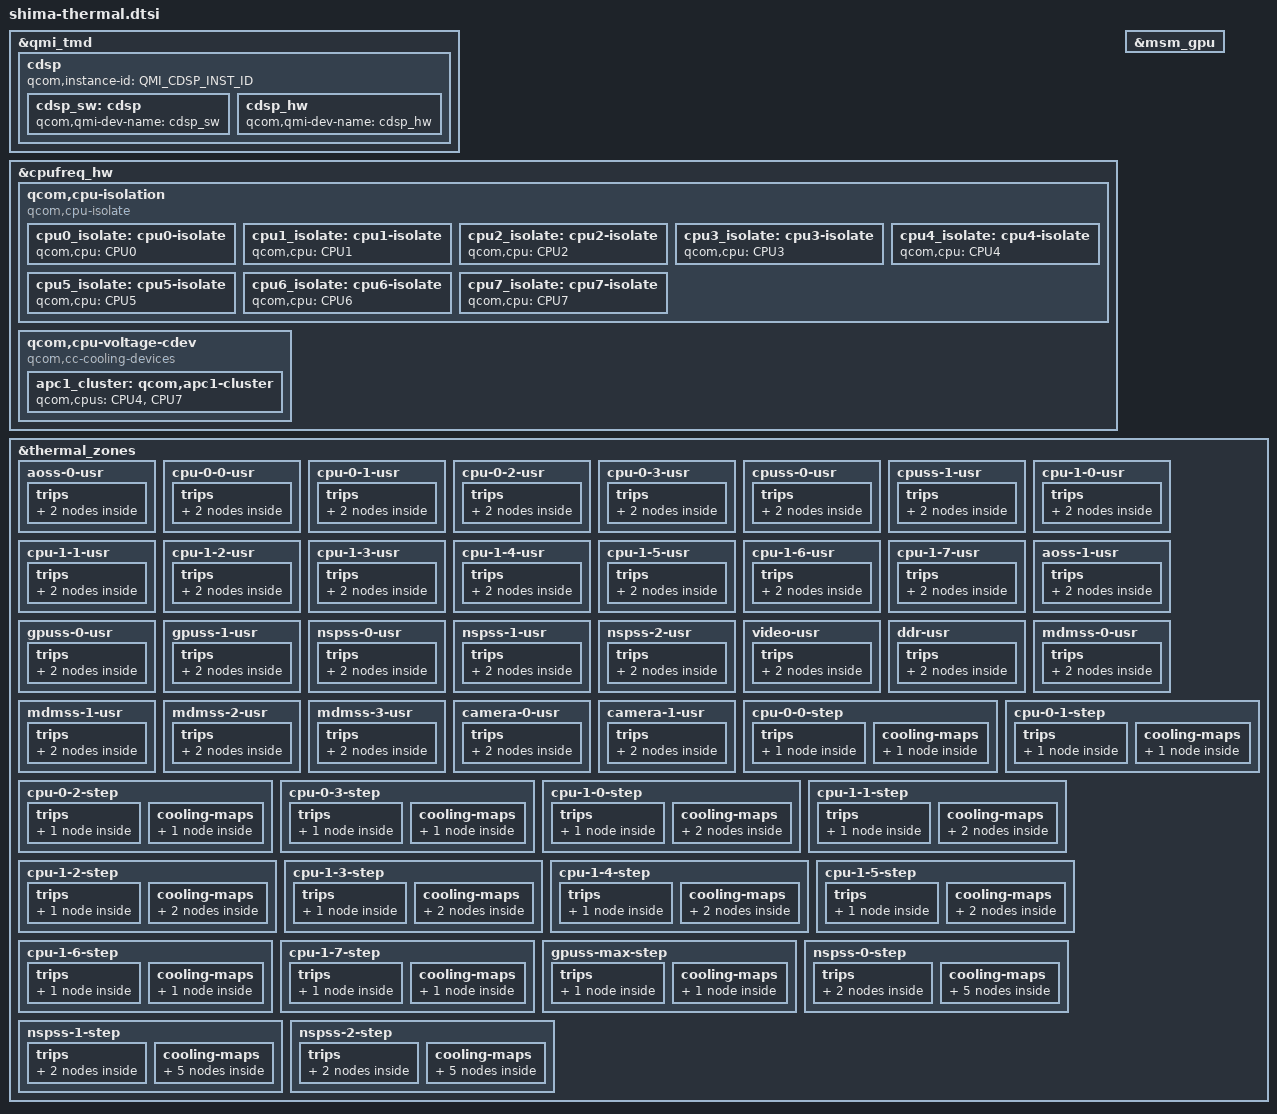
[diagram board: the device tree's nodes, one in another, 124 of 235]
#include <dt-bindings/thermal/thermal_qti.h>
#include "lahaina-thermal-modem.dtsi"

&qmi_tmd {
	cdsp {
		qcom,instance-id = <QMI_CDSP_INST_ID>;

		cdsp_sw: cdsp {
			qcom,qmi-dev-name = "cdsp_sw";
			#cooling-cells = <2>;
		};

		cdsp_hw: cdsp_hw {
			qcom,qmi-dev-name = "cdsp_hw";
			#cooling-cells = <2>;
		};
	};
};

&cpufreq_hw {
	qcom,cpu-isolation {
		compatible = "qcom,cpu-isolate";
		cpu0_isolate: cpu0-isolate {
			qcom,cpu = <&CPU0>;
			#cooling-cells = <2>;
		};

		cpu1_isolate: cpu1-isolate {
			qcom,cpu = <&CPU1>;
			#cooling-cells = <2>;
		};

		cpu2_isolate: cpu2-isolate {
			qcom,cpu = <&CPU2>;
			#cooling-cells = <2>;
		};

		cpu3_isolate: cpu3-isolate {
			qcom,cpu = <&CPU3>;
			#cooling-cells = <2>;
		};

		cpu4_isolate: cpu4-isolate {
			qcom,cpu = <&CPU4>;
			#cooling-cells = <2>;
		};

		cpu5_isolate: cpu5-isolate {
			qcom,cpu = <&CPU5>;
			#cooling-cells = <2>;
		};

		cpu6_isolate: cpu6-isolate {
			qcom,cpu = <&CPU6>;
			#cooling-cells = <2>;
		};

		cpu7_isolate: cpu7-isolate {
			qcom,cpu = <&CPU7>;
			#cooling-cells = <2>;
		};
	};

	qcom,cpu-voltage-cdev {
		compatible = "qcom,cc-cooling-devices";
		apc1_cluster: qcom,apc1-cluster {
			qcom,cpus = <&CPU4 &CPU7>;
			#cooling-cells = <2>;
		};
	};
};

&msm_gpu {
	#cooling-cells = <2>;
};

&thermal_zones {
	aoss-0-usr {
		polling-delay-passive = <0>;
		polling-delay = <0>;
		thermal-governor = "user_space";
		thermal-sensors = <&tsens0 0>;
		trips {
			active-config0 {
				temperature = <125000>;
				hysteresis = <1000>;
				type = "passive";
			};

			reset-mon-cfg {
				temperature = <115000>;
				hysteresis = <5000>;
				type = "passive";
			};
		};
	};

	cpu-0-0-usr {
		polling-delay-passive = <0>;
		polling-delay = <0>;
		thermal-governor = "user_space";
		thermal-sensors = <&tsens0 1>;
		trips {
			active-config0 {
				temperature = <125000>;
				hysteresis = <1000>;
				type = "passive";
			};

			reset-mon-cfg {
				temperature = <115000>;
				hysteresis = <5000>;
				type = "passive";
			};
		};
	};

	cpu-0-1-usr {
		polling-delay-passive = <0>;
		polling-delay = <0>;
		thermal-governor = "user_space";
		thermal-sensors = <&tsens0 2>;
		trips {
			active-config0 {
				temperature = <125000>;
				hysteresis = <1000>;
				type = "passive";
			};

			reset-mon-cfg {
				temperature = <115000>;
				hysteresis = <5000>;
				type = "passive";
			};
		};
	};

	cpu-0-2-usr {
		polling-delay-passive = <0>;
		polling-delay = <0>;
		thermal-governor = "user_space";
		thermal-sensors = <&tsens0 3>;
		trips {
			active-config0 {
				temperature = <125000>;
				hysteresis = <1000>;
				type = "passive";
			};

			reset-mon-cfg {
				temperature = <115000>;
				hysteresis = <5000>;
				type = "passive";
			};
		};
	};

	cpu-0-3-usr {
		polling-delay-passive = <0>;
		polling-delay = <0>;
		thermal-governor = "user_space";
		thermal-sensors = <&tsens0 4>;
		trips {
			active-config0 {
				temperature = <125000>;
				hysteresis = <1000>;
				type = "passive";
			};

			reset-mon-cfg {
				temperature = <115000>;
				hysteresis = <5000>;
				type = "passive";
			};
		};
	};

	cpuss-0-usr {
		polling-delay-passive = <0>;
		polling-delay = <0>;
		thermal-governor = "user_space";
		thermal-sensors = <&tsens0 5>;
		trips {
			active-config0 {
				temperature = <125000>;
				hysteresis = <1000>;
				type = "passive";
			};

			reset-mon-cfg {
				temperature = <115000>;
				hysteresis = <5000>;
				type = "passive";
			};
		};
	};

	cpuss-1-usr {
		polling-delay-passive = <0>;
		polling-delay = <0>;
		thermal-governor = "user_space";
		thermal-sensors = <&tsens0 6>;
		trips {
			active-config0 {
				temperature = <125000>;
				hysteresis = <1000>;
				type = "passive";
			};

			reset-mon-cfg {
				temperature = <115000>;
				hysteresis = <5000>;
				type = "passive";
			};
		};
	};

	cpu-1-0-usr {
		polling-delay-passive = <0>;
		polling-delay = <0>;
		thermal-governor = "user_space";
		thermal-sensors = <&tsens0 7>;
		trips {
			active-config0 {
				temperature = <125000>;
				hysteresis = <1000>;
				type = "passive";
			};

			reset-mon-cfg {
				temperature = <115000>;
				hysteresis = <5000>;
				type = "passive";
			};
		};
	};

	cpu-1-1-usr {
		polling-delay-passive = <0>;
		polling-delay = <0>;
		thermal-governor = "user_space";
		thermal-sensors = <&tsens0 8>;
		trips {
			active-config0 {
				temperature = <125000>;
				hysteresis = <1000>;
				type = "passive";
			};

			reset-mon-cfg {
				temperature = <115000>;
				hysteresis = <5000>;
				type = "passive";
			};
		};
	};

	cpu-1-2-usr {
		polling-delay-passive = <0>;
		polling-delay = <0>;
		thermal-governor = "user_space";
		thermal-sensors = <&tsens0 9>;
		trips {
			active-config0 {
				temperature = <125000>;
				hysteresis = <1000>;
				type = "passive";
			};

			reset-mon-cfg {
				temperature = <115000>;
				hysteresis = <5000>;
				type = "passive";
			};
		};
	};

	cpu-1-3-usr {
		polling-delay-passive = <0>;
		polling-delay = <0>;
		thermal-governor = "user_space";
		thermal-sensors = <&tsens0 10>;
		trips {
			active-config0 {
				temperature = <125000>;
				hysteresis = <1000>;
				type = "passive";
			};

			reset-mon-cfg {
				temperature = <115000>;
				hysteresis = <5000>;
				type = "passive";
			};
		};
	};

	cpu-1-4-usr {
		polling-delay-passive = <0>;
		polling-delay = <0>;
		thermal-governor = "user_space";
		thermal-sensors = <&tsens0 11>;
		trips {
			active-config0 {
				temperature = <125000>;
				hysteresis = <1000>;
				type = "passive";
			};

			reset-mon-cfg {
				temperature = <115000>;
				hysteresis = <5000>;
				type = "passive";
			};
		};
	};

	cpu-1-5-usr {
		polling-delay-passive = <0>;
		polling-delay = <0>;
		thermal-governor = "user_space";
		thermal-sensors = <&tsens0 12>;
		trips {
			active-config0 {
				temperature = <125000>;
				hysteresis = <1000>;
				type = "passive";
			};

			reset-mon-cfg {
				temperature = <115000>;
				hysteresis = <5000>;
				type = "passive";
			};
		};
	};

	cpu-1-6-usr {
		polling-delay-passive = <0>;
		polling-delay = <0>;
		thermal-governor = "user_space";
		thermal-sensors = <&tsens0 13>;
		trips {
			active-config0 {
				temperature = <125000>;
				hysteresis = <1000>;
				type = "passive";
			};

			reset-mon-cfg {
				temperature = <115000>;
				hysteresis = <5000>;
				type = "passive";
			};
		};
	};

	cpu-1-7-usr {
		polling-delay-passive = <0>;
		polling-delay = <0>;
		thermal-governor = "user_space";
		thermal-sensors = <&tsens0 14>;
		trips {
			active-config0 {
				temperature = <125000>;
				hysteresis = <1000>;
				type = "passive";
			};

			reset-mon-cfg {
				temperature = <115000>;
				hysteresis = <5000>;
				type = "passive";
			};
		};
	};

	aoss-1-usr {
		polling-delay-passive = <0>;
		polling-delay = <0>;
		thermal-governor = "user_space";
		thermal-sensors = <&tsens1 0>;
		trips {
			active-config0 {
				temperature = <125000>;
				hysteresis = <1000>;
				type = "passive";
			};

			reset-mon-cfg {
				temperature = <115000>;
				hysteresis = <5000>;
				type = "passive";
			};
		};
	};

	gpuss-0-usr {
		polling-delay-passive = <0>;
		polling-delay = <0>;
		thermal-governor = "user_space";
		thermal-sensors = <&tsens1 1>;
		trips {
			active-config0 {
				temperature = <125000>;
				hysteresis = <1000>;
				type = "passive";
			};

			reset-mon-cfg {
				temperature = <115000>;
				hysteresis = <5000>;
				type = "passive";
			};
		};
	};

	gpuss-1-usr {
		polling-delay-passive = <0>;
		polling-delay = <0>;
		thermal-governor = "user_space";
		thermal-sensors = <&tsens1 2>;
		trips {
			active-config0 {
				temperature = <125000>;
				hysteresis = <1000>;
				type = "passive";
			};

			reset-mon-cfg {
				temperature = <115000>;
				hysteresis = <5000>;
				type = "passive";
			};
		};
	};

	nspss-0-usr {
		polling-delay-passive = <0>;
		polling-delay = <0>;
		thermal-governor = "user_space";
		thermal-sensors = <&tsens1 3>;
		trips {
			active-config0 {
				temperature = <125000>;
				hysteresis = <1000>;
				type = "passive";
			};

			reset-mon-cfg {
				temperature = <115000>;
				hysteresis = <5000>;
				type = "passive";
			};
		};
	};

	nspss-1-usr {
		polling-delay-passive = <0>;
		polling-delay = <0>;
		thermal-governor = "user_space";
		thermal-sensors = <&tsens1 4>;
		trips {
			active-config0 {
				temperature = <125000>;
				hysteresis = <1000>;
				type = "passive";
			};

			reset-mon-cfg {
				temperature = <115000>;
				hysteresis = <5000>;
				type = "passive";
			};
		};
	};

	nspss-2-usr {
		polling-delay-passive = <0>;
		polling-delay = <0>;
		thermal-governor = "user_space";
		thermal-sensors = <&tsens1 5>;
		trips {
			active-config0 {
				temperature = <125000>;
				hysteresis = <1000>;
				type = "passive";
			};

			reset-mon-cfg {
				temperature = <115000>;
				hysteresis = <5000>;
				type = "passive";
			};
		};
	};

	video-usr {
		polling-delay-passive = <0>;
		polling-delay = <0>;
		thermal-governor = "user_space";
		thermal-sensors = <&tsens1 6>;
		trips {
			active-config0 {
				temperature = <125000>;
				hysteresis = <1000>;
				type = "passive";
			};

			reset-mon-cfg {
				temperature = <115000>;
				hysteresis = <5000>;
				type = "passive";
			};
		};
	};

	ddr-usr {
		polling-delay-passive = <0>;
		polling-delay = <0>;
		thermal-governor = "user_space";
		thermal-sensors = <&tsens1 7>;
		trips {
			active-config0 {
				temperature = <125000>;
				hysteresis = <1000>;
				type = "passive";
			};

			reset-mon-cfg {
				temperature = <115000>;
				hysteresis = <5000>;
				type = "passive";
			};
		};
	};

	mdmss-0-usr {
		polling-delay-passive = <0>;
		polling-delay = <0>;
		thermal-governor = "user_space";
		thermal-sensors = <&tsens1 8>;
		trips {
			active-config0 {
				temperature = <125000>;
				hysteresis = <1000>;
				type = "passive";
			};

			reset-mon-cfg {
				temperature = <115000>;
				hysteresis = <5000>;
				type = "passive";
			};
		};
	};

	mdmss-1-usr {
		polling-delay-passive = <0>;
		polling-delay = <0>;
		thermal-governor = "user_space";
		thermal-sensors = <&tsens1 9>;
		trips {
			active-config0 {
				temperature = <125000>;
				hysteresis = <1000>;
				type = "passive";
			};

			reset-mon-cfg {
				temperature = <115000>;
				hysteresis = <5000>;
				type = "passive";
			};
		};
	};

	mdmss-2-usr {
		polling-delay-passive = <0>;
		polling-delay = <0>;
		thermal-governor = "user_space";
		thermal-sensors = <&tsens1 10>;
		trips {
			active-config0 {
				temperature = <125000>;
				hysteresis = <1000>;
				type = "passive";
			};

			reset-mon-cfg {
				temperature = <115000>;
				hysteresis = <5000>;
				type = "passive";
			};
		};
	};

	mdmss-3-usr {
		polling-delay-passive = <0>;
		polling-delay = <0>;
		thermal-governor = "user_space";
		thermal-sensors = <&tsens1 11>;
		trips {
			active-config0 {
				temperature = <125000>;
				hysteresis = <1000>;
				type = "passive";
			};

			reset-mon-cfg {
				temperature = <115000>;
				hysteresis = <5000>;
				type = "passive";
			};
		};
	};

	camera-0-usr {
		polling-delay-passive = <0>;
		polling-delay = <0>;
		thermal-governor = "user_space";
		thermal-sensors = <&tsens1 12>;
		trips {
			active-config0 {
				temperature = <125000>;
				hysteresis = <1000>;
				type = "passive";
			};

			reset-mon-cfg {
				temperature = <115000>;
				hysteresis = <5000>;
				type = "passive";
			};
		};
	};

	camera-1-usr {
		polling-delay-passive = <0>;
		polling-delay = <0>;
		thermal-governor = "user_space";
		thermal-sensors = <&tsens1 13>;
		trips {
			active-config0 {
				temperature = <125000>;
				hysteresis = <1000>;
				type = "passive";
			};

			reset-mon-cfg {
				temperature = <115000>;
				hysteresis = <5000>;
				type = "passive";
			};
		};
	};

	cpu-0-0-step {
		polling-delay-passive = <0>;
		polling-delay = <0>;
		thermal-governor = "step_wise";
		thermal-sensors = <&tsens0 1>;
		trips {
			cpu00_config: cpu00-config {
				temperature = <110000>;
				hysteresis = <10000>;
				type = "passive";
			};
		};

		cooling-maps {
			cpu00_cdev {
				trip = <&cpu00_config>;
				cooling-device = <&cpu0_isolate 1 1>;
			};
		};
	};

	cpu-0-1-step {
		polling-delay-passive = <0>;
		polling-delay = <0>;
		thermal-governor = "step_wise";
		thermal-sensors = <&tsens0 2>;
		trips {
			cpu01_config: cpu01-config {
				temperature = <110000>;
				hysteresis = <10000>;
				type = "passive";
			};
		};

		cooling-maps {
			cpu01_cdev {
				trip = <&cpu01_config>;
				cooling-device = <&cpu1_isolate 1 1>;
			};
		};
	};

	cpu-0-2-step {
		polling-delay-passive = <0>;
		polling-delay = <0>;
		thermal-governor = "step_wise";
		thermal-sensors = <&tsens0 3>;
		trips {
			cpu02_config: cpu02-config {
				temperature = <110000>;
				hysteresis = <10000>;
				type = "passive";
			};
		};

		cooling-maps {
			cpu02_cdev {
				trip = <&cpu02_config>;
				cooling-device = <&cpu2_isolate 1 1>;
			};
		};
	};

	cpu-0-3-step {
		polling-delay-passive = <0>;
		polling-delay = <0>;
		thermal-sensors = <&tsens0 4>;
		thermal-governor = "step_wise";
		trips {
			cpu03_config: cpu03-config {
				temperature = <110000>;
				hysteresis = <10000>;
				type = "passive";
			};
		};

		cooling-maps {
			cpu03_cdev {
				trip = <&cpu03_config>;
				cooling-device = <&cpu3_isolate 1 1>;
			};
		};
	};

	cpu-1-0-step {
		polling-delay-passive = <0>;
		polling-delay = <0>;
		thermal-sensors = <&tsens0 7>;
		thermal-governor = "step_wise";
		trips {
			cpu10_config: cpu10-config {
				temperature = <110000>;
				hysteresis = <10000>;
				type = "passive";
			};
		};

		cooling-maps {
			cpu10_cdev {
				trip = <&cpu10_config>;
				cooling-device = <&cpu4_isolate 1 1>;
			};

			cpu10_cdev1 {
				trip = <&cpu10_config>;
				cooling-device = <&CPU4 THERMAL_MAX_LIMIT
							THERMAL_MAX_LIMIT>;
			};
		};
	};

	cpu-1-1-step {
		polling-delay-passive = <0>;
		polling-delay = <0>;
		thermal-sensors = <&tsens0 8>;
		thermal-governor = "step_wise";
		trips {
			cpu11_config: cpu11-config {
				temperature = <110000>;
				hysteresis = <10000>;
				type = "passive";
			};
		};

		cooling-maps {
			cpu11_cdev {
				trip = <&cpu11_config>;
				cooling-device = <&cpu4_isolate 1 1>;
			};

			cpu11_cdev1 {
				trip = <&cpu11_config>;
				cooling-device = <&CPU4 THERMAL_MAX_LIMIT
							THERMAL_MAX_LIMIT>;
			};
		};
	};

	cpu-1-2-step {
		polling-delay-passive = <0>;
		polling-delay = <0>;
		thermal-sensors = <&tsens0 9>;
		thermal-governor = "step_wise";
		trips {
			cpu12_config: cpu12-config {
				temperature = <110000>;
				hysteresis = <10000>;
				type = "passive";
			};
		};

		cooling-maps {
			cpu12_cdev {
				trip = <&cpu12_config>;
				cooling-device = <&cpu5_isolate 1 1>;
			};

			cpu12_cdev1 {
				trip = <&cpu12_config>;
				cooling-device = <&CPU4 THERMAL_MAX_LIMIT
							THERMAL_MAX_LIMIT>;
			};
		};
	};

	cpu-1-3-step {
		polling-delay-passive = <0>;
		polling-delay = <0>;
		thermal-sensors = <&tsens0 10>;
		thermal-governor = "step_wise";
		trips {
			cpu13_config: cpu13-config {
				temperature = <110000>;
				hysteresis = <10000>;
				type = "passive";
			};
		};

		cooling-maps {
			cpu13_cdev {
				trip = <&cpu13_config>;
				cooling-device = <&cpu5_isolate 1 1>;
			};

			cpu13_cdev1 {
				trip = <&cpu13_config>;
				cooling-device = <&CPU4 THERMAL_MAX_LIMIT
							THERMAL_MAX_LIMIT>;
			};
		};
	};

	cpu-1-4-step {
		polling-delay-passive = <0>;
		polling-delay = <0>;
		thermal-sensors = <&tsens0 11>;
		thermal-governor = "step_wise";
		trips {
			cpu14_config: cpu14-config {
				temperature = <110000>;
				hysteresis = <10000>;
				type = "passive";
			};
		};

		cooling-maps {
			cpu14_cdev {
				trip = <&cpu14_config>;
				cooling-device = <&cpu6_isolate 1 1>;
			};

			cpu14_cdev1 {
				trip = <&cpu14_config>;
				cooling-device = <&CPU4 THERMAL_MAX_LIMIT
							THERMAL_MAX_LIMIT>;
			};
		};
	};

	cpu-1-5-step {
		polling-delay-passive = <0>;
		polling-delay = <0>;
		thermal-sensors = <&tsens0 12>;
		thermal-governor = "step_wise";
		trips {
			cpu15_config: cpu15-config {
				temperature = <110000>;
				hysteresis = <10000>;
				type = "passive";
			};
		};

		cooling-maps {
			cpu15_cdev {
				trip = <&cpu15_config>;
				cooling-device = <&cpu6_isolate 1 1>;
			};

			cpu15_cdev1 {
				trip = <&cpu15_config>;
				cooling-device = <&CPU4 THERMAL_MAX_LIMIT
							THERMAL_MAX_LIMIT>;
			};
		};
	};

	cpu-1-6-step {
		polling-delay-passive = <0>;
		polling-delay = <0>;
		thermal-sensors = <&tsens0 13>;
		thermal-governor = "step_wise";
		trips {
			cpu16_config: cpu16-config {
				temperature = <110000>;
				hysteresis = <10000>;
				type = "passive";
			};
		};

		cooling-maps {
			cpu16_cdev {
				trip = <&cpu16_config>;
				cooling-device = <&cpu7_isolate 1 1>;
			};
		};
	};

	cpu-1-7-step {
		polling-delay-passive = <0>;
		polling-delay = <0>;
		thermal-sensors = <&tsens0 14>;
		thermal-governor = "step_wise";
		trips {
			cpu17_config: cpu17-config {
				temperature = <110000>;
				hysteresis = <10000>;
				type = "passive";
			};
		};

		cooling-maps {
			cpu17_cdev {
				trip = <&cpu17_config>;
				cooling-device = <&cpu7_isolate 1 1>;
			};
		};
	};

	gpuss-max-step {
		polling-delay-passive = <10>;
		polling-delay = <100>;
		thermal-governor = "step_wise";
		thermal-sensors = <&tsens1 1>, <&tsens1 2>;
		sensor-aggregation = <AGGREGATE_MAX_VALUE>;
		trips {
			gpuss_config: active-config0 {
				temperature = <95000>;
				hysteresis = <0>;
				type = "passive";
			};
		};

		cooling-maps {
			gpu_cdev {
				trip = <&gpuss_config>;
				cooling-device = <&msm_gpu THERMAL_NO_LIMIT
							THERMAL_NO_LIMIT>;
			};
		};
	};

	nspss-0-step {
		polling-delay-passive = <10>;
		polling-delay = <0>;
		thermal-governor = "step_wise";
		thermal-sensors = <&tsens1 3>;
		trips {
			nspss0_trip0: nspss0-trip0 {
				temperature = <95000>;
				hysteresis = <0>;
				type = "passive";
			};

			nspss0_trip1: nspss0-trip1 {
				temperature = <100000>;
				hysteresis = <5000>;
				type = "passive";
			};
		};

		cooling-maps {
			cdsp-cdev0 {
				trip = <&nspss0_trip0>;
				cooling-device = <&cdsp_sw THERMAL_NO_LIMIT
							THERMAL_NO_LIMIT>;
			};

			cdsp-cdev1 {
				trip = <&nspss0_trip1>;
				cooling-device = <&cdsp_sw THERMAL_MAX_LIMIT
							THERMAL_MAX_LIMIT>;
			};

			gpu_cdev {
				trip = <&nspss0_trip1>;
				cooling-device = <&msm_gpu (THERMAL_MAX_LIMIT-1)
							(THERMAL_MAX_LIMIT-1)>;
			};

			modem-pa-cdev {
				trip = <&nspss0_trip1>;
				cooling-device = <&modem_pa 3 3>;
			};

			modem-tj-cdev {
				trip = <&nspss0_trip1>;
				cooling-device = <&modem_tj 3 3>;
			};
		};
	};

	nspss-1-step {
		polling-delay-passive = <10>;
		polling-delay = <0>;
		thermal-governor = "step_wise";
		thermal-sensors = <&tsens1 4>;
		trips {
			nspss1_trip0: nspss1-trip0 {
				temperature = <95000>;
				hysteresis = <0>;
				type = "passive";
			};

			nspss1_trip1: nspss1-trip1 {
				temperature = <100000>;
				hysteresis = <5000>;
				type = "passive";
			};
		};

		cooling-maps {
			cdsp-cdev0 {
				trip = <&nspss1_trip0>;
				cooling-device = <&cdsp_sw THERMAL_NO_LIMIT
							THERMAL_NO_LIMIT>;
			};

			cdsp-cdev1 {
				trip = <&nspss1_trip1>;
				cooling-device = <&cdsp_sw THERMAL_MAX_LIMIT
							THERMAL_MAX_LIMIT>;
			};

			gpu_cdev {
				trip = <&nspss1_trip1>;
				cooling-device = <&msm_gpu (THERMAL_MAX_LIMIT-1)
							(THERMAL_MAX_LIMIT-1)>;
			};

			modem-pa-cdev {
				trip = <&nspss1_trip1>;
				cooling-device = <&modem_pa 3 3>;
			};

			modem-tj-cdev {
				trip = <&nspss1_trip1>;
				cooling-device = <&modem_tj 3 3>;
			};
		};
	};

	nspss-2-step {
		polling-delay-passive = <10>;
		polling-delay = <0>;
		thermal-governor = "step_wise";
		thermal-sensors = <&tsens1 5>;
		trips {
			nspss2_trip0: nspss2-trip0 {
				temperature = <95000>;
				hysteresis = <0>;
				type = "passive";
			};

			nspss2_trip1: nspss2-trip1 {
				temperature = <100000>;
				hysteresis = <5000>;
				type = "passive";
			};
		};

		cooling-maps {
			cdsp-cdev0 {
				trip = <&nspss2_trip0>;
				cooling-device = <&cdsp_sw THERMAL_NO_LIMIT
							THERMAL_NO_LIMIT>;
			};

			cdsp-cdev1 {
				trip = <&nspss2_trip1>;
				cooling-device = <&cdsp_sw THERMAL_MAX_LIMIT
							THERMAL_MAX_LIMIT>;
			};

			gpu_cdev {
				trip = <&nspss2_trip1>;
				cooling-device = <&msm_gpu (THERMAL_MAX_LIMIT-1)
							(THERMAL_MAX_LIMIT-1)>;
			};

			modem-pa-cdev {
				trip = <&nspss2_trip1>;
				cooling-device = <&modem_pa 3 3>;
			};

			modem-tj-cdev {
				trip = <&nspss2_trip1>;
				cooling-device = <&modem_tj 3 3>;
			};
		};
	};
};

